# PIC18F56Q84 register map
Vendor: Microchip
Registers are 8-bit, read-write, reset 0x0 unless marked. A register's access mark holds for its fields unless they carry their own. Addresses are absolute, and some are shared; only a register's first bit layout is shown; [hi:lo] are bit positions; {n}, {i} and the like mark numbered series.

## nvm_scan
0x35A SCANLADRL
  [7:0] LADR
0x35B SCANLADRH
  [7:0] LADR
0x35C SCANLADRU
  [5:0] LADR
0x35D SCANHADRL reset 0xFF
  [7:0] HADR
0x35E SCANHADRH reset 0xFF
  [7:0] HADR
0x35F SCANHADRU reset 0x3F
  [5:0] HADR
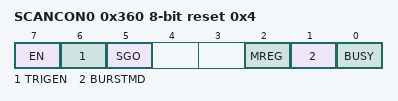
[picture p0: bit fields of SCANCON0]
0x360 SCANCON0 reset 0x4
  [7] EN, [6] TRIGEN, [5] SGO, [2] MREG, [1] BURSTMD, [0] BUSY
0x361 SCANTRIG
  [4:0] TSEL

## wg_cwg
{0x3B3+9i} CWG{i}CLK (i=1..3)
  [0] CS
{0x3B4+9i} CWG{i}ISM (i=1..3)
  [4:0] IS
{0x3B5+9i} CWG{i}DBR (i=1..3)
  [5:0] DBR
{0x3B6+9i} CWG{i}DBF (i=1..3)
  [5:0] DBF
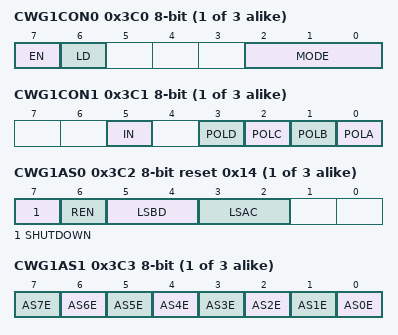
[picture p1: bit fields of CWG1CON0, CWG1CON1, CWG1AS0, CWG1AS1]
{0x3B7+9i} CWG{i}CON0 (i=1..3)
  [7] EN, [6] LD, [2:0] MODE
{0x3B8+9i} CWG{i}CON1 reset not defined (i=1..3) — (power-on value --x-0000)
  [5] IN ro, [3] POLD, [2] POLC, [1] POLB, [0] POLA
{0x3B9+9i} CWG{i}AS0 reset 0x14 (i=1..3)
  [7] SHUTDOWN, [6] REN, [5:4] LSBD, [3:2] LSAC
{0x3BA+9i} CWG{i}AS1 (i=1..3)
  [n] AS{n}E (n=0..7)
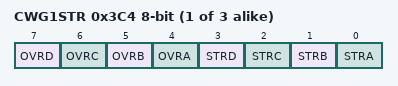
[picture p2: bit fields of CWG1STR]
{0x3BB+9i} CWG{i}STR (i=1..3)
  [7] OVRD, [6] OVRC, [5] OVRB, [4] OVRA, [3] STRD, [2] STRC, [1] STRB, [0] STRA

## amp_fvr_ts_ctrl
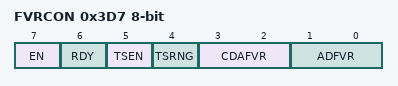
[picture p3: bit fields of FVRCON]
0x3D7 FVRCON reset not defined — (power-on value xx000000)
  [7] EN — Zero-Cross Detect Software Enable bit
  [6] RDY ro
  [5] TSEN — Zero-Cross Detect Data Output
  [4] TSRNG — Zero-Cross Detect Polarity bit
  [3:2] CDAFVR
  [1:0] ADFVR — Zero-Cross Detect Positive-going Edge Interrupt Enable

## adc_sarcore_mp_ctrl
0x3D9 ADLTHL
  [7:0] LTH
0x3DA ADLTHH
  [7:0] LTH
0x3DB ADUTHL
  [7:0] UTH
0x3DC ADUTHH
  [7:0] UTH
0x3DD ADERRL ro reset not defined — (power-on value xxxxxxxx)
  [7:0] ERR
0x3DE ADERRH ro reset not defined — (power-on value xxxxxxxx)
  [7:0] ERR
0x3DF ADSTPTL
  [7:0] STPT
0x3E0 ADSTPTH
  [7:0] STPT
0x3E1 ADFLTRL ro reset not defined — (power-on value xxxxxxxx)
  [7:0] FLTR
0x3E2 ADFLTRH ro reset not defined — (power-on value xxxxxxxx)
  [7:0] FLTR
0x3E3 ADACCL reset not defined — (power-on value xxxxxxxx)
  [7:0] ACC
0x3E4 ADACCH reset not defined — (power-on value xxxxxxxx)
  [7:0] ACC
0x3E5 ADACCU reset not defined — (power-on value ------xx)
  [1:0] ACC
0x3E6 ADCNT reset not defined — (power-on value xxxxxxxx)
  [7:0] CNT
0x3E7 ADRPT
  [7:0] RPT
0x3E8 ADPREVL ro reset not defined — (power-on value xxxxxxxx)
  [7:0] PREV
0x3E9 ADPREVH ro reset not defined — (power-on value xxxxxxxx)
  [7:0] PREV
0x3EA ADRESL
  [7:0] RES
0x3EB ADRESH
  [7:0] RES
0x3EC ADPCH
  [5:0] ADPCH
0x3EE ADACQL
  [7:0] ACQ
0x3EF ADACQH
  [4:0] ACQ
0x3F0 ADCAP
  [4:0] ADCAP
0x3F1 ADPREL
  [7:0] PRE
0x3F2 ADPREH
  [4:0] PRE
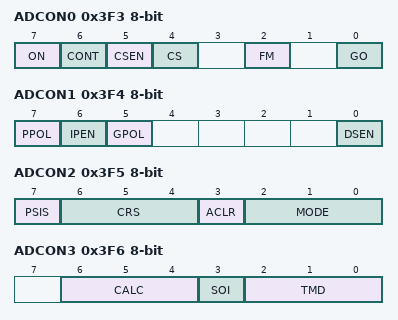
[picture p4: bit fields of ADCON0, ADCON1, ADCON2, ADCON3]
0x3F3 ADCON0 reset not defined — (power-on value 00x0-0-0)
  [7] ON, [6] CONT, [5] CSEN, [4] CS, [2] FM, [0] GO
0x3F4 ADCON1
  [7] PPOL, [6] IPEN, [5] GPOL, [0] DSEN
0x3F5 ADCON2
  [7] PSIS, [6:4] CRS, [3] ACLR, [2:0] MODE
0x3F6 ADCON3
  [6:4] CALC, [3] SOI, [2:0] TMD
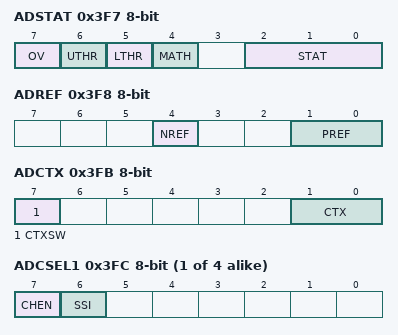
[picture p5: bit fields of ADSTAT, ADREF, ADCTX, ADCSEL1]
0x3F7 ADSTAT
  [7] OV ro
  [6] UTHR ro
  [5] LTHR ro
  [4] MATH — (can only be cleared)
  [2:0] STAT ro
0x3F8 ADREF
  [4] NREF, [1:0] PREF
0x3F9 ADACT
  [5:0] ACT
0x3FA ADCLK
  [5:0] CS
0x3FB ADCTX
  [7] CTXSW, [1:0] CTX
{0x3FB+i} ADCSEL{i} reset not defined (i=1..4) — (power-on value 0x------)
  [7] CHEN, [6] SSI

## DOS_xxxxx_port_control
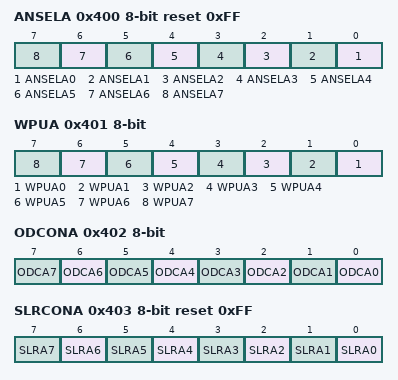
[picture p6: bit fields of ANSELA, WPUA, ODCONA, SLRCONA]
0x400 ANSELA reset 0xFF
  [n] ANSELA{n} (n=0..7)
0x401 WPUA
  [n] WPUA{n} (n=0..7)
0x402 ODCONA
  [n] ODCA{n} (n=0..7)
0x403 SLRCONA reset 0xFF
  [n] SLRA{n} (n=0..7)
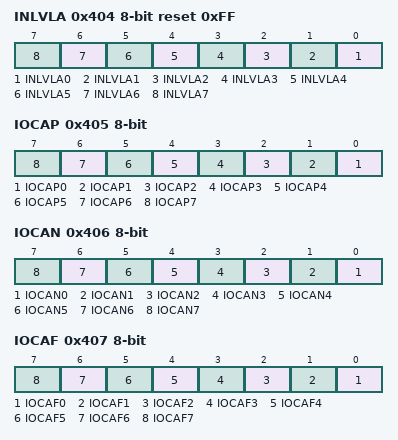
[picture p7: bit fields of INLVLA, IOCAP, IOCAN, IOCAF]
0x404 INLVLA reset 0xFF
  [n] INLVLA{n} (n=0..7)
0x405 IOCAP
  [n] IOCAP{n} (n=0..7)
0x406 IOCAN
  [n] IOCAN{n} (n=0..7)
0x407 IOCAF
  [n] IOCAF{n} (n=0..7)
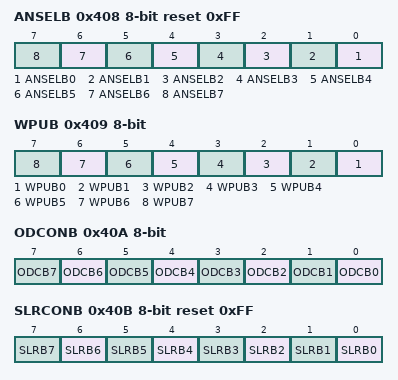
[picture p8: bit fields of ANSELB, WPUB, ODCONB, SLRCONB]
0x408 ANSELB reset 0xFF
  [n] ANSELB{n} (n=0..7)
0x409 WPUB
  [n] WPUB{n} (n=0..7)
0x40A ODCONB
  [n] ODCB{n} (n=0..7)
0x40B SLRCONB reset 0xFF
  [n] SLRB{n} (n=0..7)
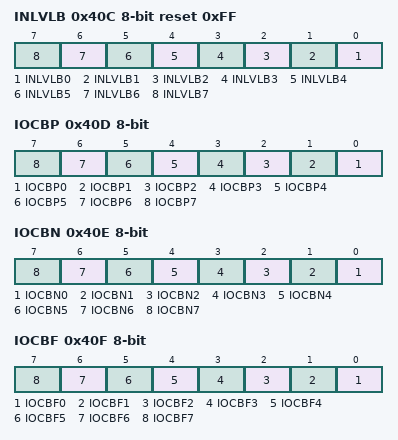
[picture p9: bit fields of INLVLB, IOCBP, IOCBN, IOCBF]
0x40C INLVLB reset 0xFF
  [n] INLVLB{n} (n=0..7)
0x40D IOCBP
  [n] IOCBP{n} (n=0..7)
0x40E IOCBN
  [n] IOCBN{n} (n=0..7)
0x40F IOCBF
  [n] IOCBF{n} (n=0..7)
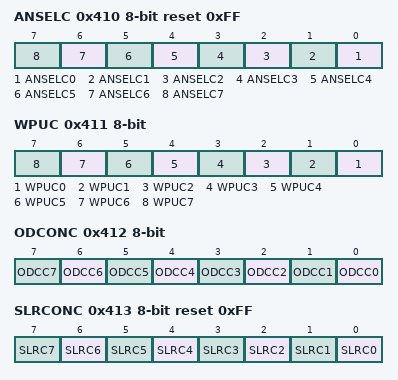
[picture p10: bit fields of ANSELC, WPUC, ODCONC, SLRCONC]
0x410 ANSELC reset 0xFF
  [n] ANSELC{n} (n=0..7)
0x411 WPUC
  [n] WPUC{n} (n=0..7)
0x412 ODCONC
  [n] ODCC{n} (n=0..7)
0x413 SLRCONC reset 0xFF
  [n] SLRC{n} (n=0..7)
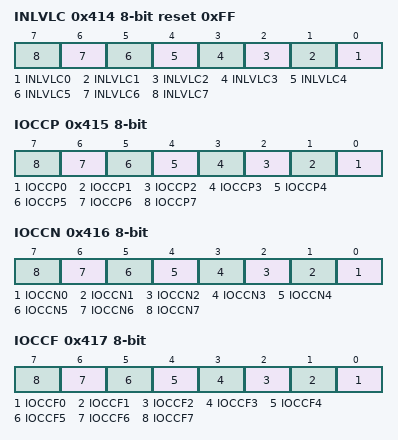
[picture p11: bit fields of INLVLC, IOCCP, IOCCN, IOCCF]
0x414 INLVLC reset 0xFF
  [n] INLVLC{n} (n=0..7)
0x415 IOCCP
  [n] IOCCP{n} (n=0..7)
0x416 IOCCN
  [n] IOCCN{n} (n=0..7)
0x417 IOCCF
  [n] IOCCF{n} (n=0..7)
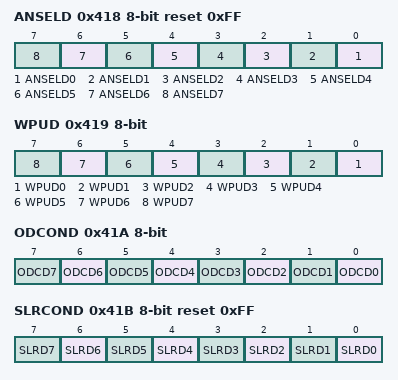
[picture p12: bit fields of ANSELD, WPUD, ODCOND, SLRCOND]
0x418 ANSELD reset 0xFF
  [n] ANSELD{n} (n=0..7)
0x419 WPUD
  [n] WPUD{n} (n=0..7)
0x41A ODCOND
  [n] ODCD{n} (n=0..7)
0x41B SLRCOND reset 0xFF
  [n] SLRD{n} (n=0..7)
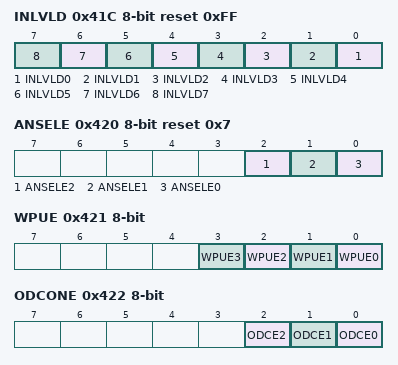
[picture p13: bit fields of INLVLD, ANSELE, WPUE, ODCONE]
0x41C INLVLD reset 0xFF
  [n] INLVLD{n} (n=0..7)
0x420 ANSELE reset 0x7
  [2] ANSELE2, [1] ANSELE1, [0] ANSELE0
0x421 WPUE
  [n] WPUE{n} (n=0..3)
0x422 ODCONE
  [2] ODCE2, [1] ODCE1, [0] ODCE0
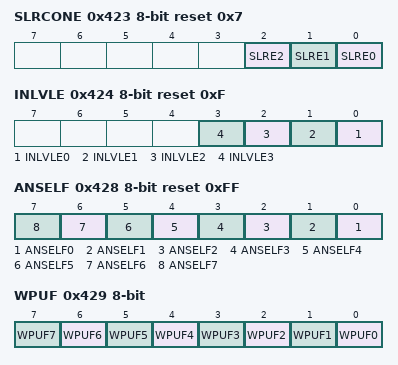
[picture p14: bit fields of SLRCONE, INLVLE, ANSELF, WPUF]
0x423 SLRCONE reset 0x7
  [2] SLRE2, [1] SLRE1, [0] SLRE0
0x424 INLVLE reset 0xF
  [n] INLVLE{n} (n=0..3)
0x425 IOCEP
  [3] IOCEP3
0x426 IOCEN
  [3] IOCEN3
0x427 IOCEF
  [3] IOCEF3
0x428 ANSELF reset 0xFF
  [n] ANSELF{n} (n=0..7)
0x429 WPUF
  [n] WPUF{n} (n=0..7)
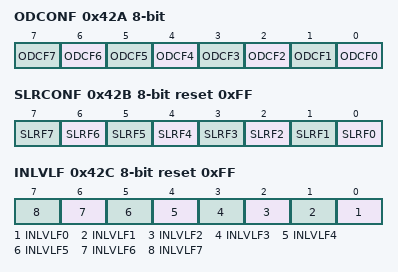
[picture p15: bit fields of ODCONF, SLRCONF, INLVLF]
0x42A ODCONF
  [n] ODCF{n} (n=0..7)
0x42B SLRCONF reset 0xFF
  [n] SLRF{n} (n=0..7)
0x42C INLVLF reset 0xFF
  [n] INLVLF{n} (n=0..7)

## tmr_dds
{0x438+8i} NCO{i}ACCL (i=1..3)
  [7:0] ACC
{0x439+8i} NCO{i}ACCH (i=1..3)
  [7:0] ACC
{0x43A+8i} NCO{i}ACCU (i=1..3)
  [3:0] ACC
{0x43B+8i} NCO{i}INCL reset 0x1 (i=1..3)
  [7:0] INC
{0x43C+8i} NCO{i}INCH (i=1..3)
  [7:0] INC
{0x43D+8i} NCO{i}INCU (i=1..3)
  [3:0] INC
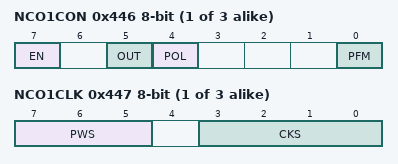
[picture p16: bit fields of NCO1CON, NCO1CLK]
{0x43E+8i} NCO{i}CON (i=1..3) — Configurable logic cell control
  [7] EN, [5] OUT ro, [4] POL, [0] PFM
{0x43F+8i} NCO{i}CLK (i=1..3)
  [7:5] PWS, [3:0] CKS

## int
0x459 IVTLOCK
  [0] IVTLOCKED
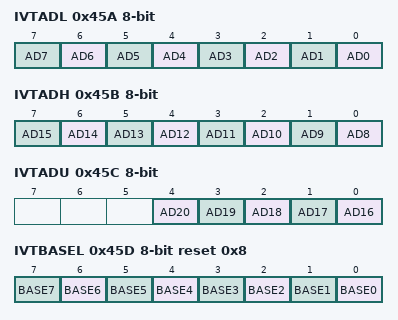
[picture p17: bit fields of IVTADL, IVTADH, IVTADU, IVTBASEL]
0x45A IVTADL
  [n] AD{n} (n=0..7)
0x45B IVTADH
  [n-8] AD{n} (n=8..15)
0x45C IVTADU
  [n-16] AD{n} (n=16..20)
0x45D IVTBASEL reset 0x8
  [n] BASE{n} (n=0..7)
0x45E IVTBASEH
  [n-8] BASE{n} (n=8..15)
0x45F IVTBASEU
  [n-16] BASE{n} (n=16..20)
0x4D6 INTCON0 reset 0x7
  [7] GIE, [6] GIEL, [5] IPEN, [2] INT2EDG, [1] INT1EDG, [0] INT0EDG
0x4D7 INTCON1 ro
  [7:6] STAT

## pwm_cmp
{0x451+0xF*i} PWM{i}ERS (i=1..4)
  [7:0] ERS
{0x452+0xF*i} PWM{i}CLK (i=1..4)
  [7:0] CLK
{0x453+0xF*i} PWM{i}LDS (i=1..4)
  [7:0] LDS
{0x454+0xF*i} PWM{i}PRL (i=1..4)
  [7:0] PRL
{0x455+0xF*i} PWM{i}PRH (i=1..4)
  [7:0] PRH
{0x456+0xF*i} PWM{i}CPRE (i=1..4)
  [7:0] CPRE
{0x457+0xF*i} PWM{i}PIPOS (i=1..4)
  [7:0] PIPOS
{0x458+0xF*i} PWM{i}GIR (i=1..4)
  [1] S1P2IF, [0] S1P1IF
{0x459+0xF*i} PWM{i}GIE (i=1..4)
  [1] S1P2IE, [0] S1P1IE
{0x45A+0xF*i} PWM{i}CON (i=1..4)
  [7] EN, [2] LD, [1] ERSPOL, [0] ERSNOW
{0x45B+0xF*i} PWM{i}S1CFG (i=1..4)
  [7] POL2, [6] POL1, [3] PPEN, [2:0] MODE
{0x45C+0xF*i} PWM{i}S1P1L (i=1..4)
  [7:0] S1P1L
{0x45D+0xF*i} PWM{i}S1P1H (i=1..4)
  [7:0] S1P1H
{0x45E+0xF*i} PWM{i}S1P2L (i=1..4)
  [7:0] S1P2L
{0x45F+0xF*i} PWM{i}S1P2H (i=1..4)
  [7:0] S1P2H
